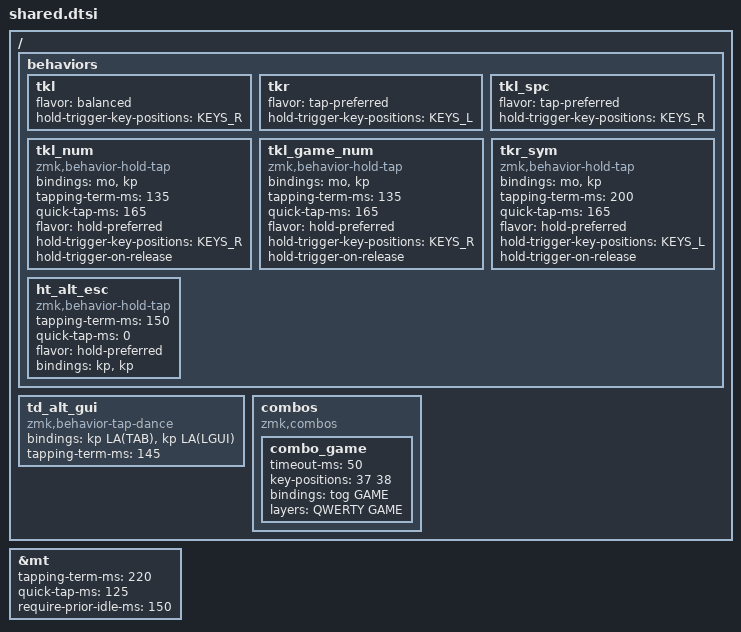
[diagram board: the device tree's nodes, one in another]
/* Key Positions
╭────────────────────────╮ ╭────────────────────────╮
│  0   1   2   3   4   5 │ │  6   7   8   9  10  11 │
│ 12  13  14  15  16  17 │ │ 18  19  20  21  22  23 │
│ 24  25  26  27  28  29 │ │ 30  31  32  33  34  35 │
╰───────────╮ 36  37  38 │ │ 39  40  41 ╭───────────╯
            ╰────────────╯ ╰────────────╯
*/


#define KEYS_L 0 1 2 3 4 5 12 13 14 15 16 17 24 25 26 27 28 29 36 37 38
#define KEYS_R 6 7 8 9 10 11 18 19 20 21 22 23 30 31 32 33 34 35 39 40 41

// layers
#define QWERTY    0
#define COLEMAK   1
#define GAME      2
#define GAME_NUM  3
#define NUM       4
#define FN        5
#define MEDIA     6
#define MOUSE     7
#define SYM       8

#define alt_esc      ht_alt_esc    LALT     ESC
#define fn_spc       tkl_spc       FN       SPACE
#define num_esc      tkl_num       NUM      ESC
#define game_num_esc tkl_game_num GAME_NUM ESC
#define mo_bspc      tkr           MOUSE    BSPC
#define sym_ret   tkr_sym    SYM      RET
#define media_del tkr        MEDIA    DEL

#define HOLD_TAP_BASE \
    compatible = "zmk,behavior-hold-tap"; \
    #binding-cells = <2>; \
    bindings = <&mo>, <&kp>; \
    tapping-term-ms = <165>; \
    quick-tap-ms = <145>; \
    require-prior-idle-ms = <100>;


&mt {
  tapping-term-ms = <220>;
  quick-tap-ms = <125>;
  require-prior-idle-ms = <150>;
};

/ {
  behaviors {
    tkl: tkl {
      HOLD_TAP_BASE
      flavor = "balanced";
      hold-trigger-key-positions = <KEYS_R>;
    };

    tkr: tkr {
      HOLD_TAP_BASE
      flavor = "tap-preferred";
      hold-trigger-key-positions = <KEYS_L>;
    };

    tkl_spc: tkl_spc {
      HOLD_TAP_BASE
      flavor = "tap-preferred";
      hold-trigger-key-positions = <KEYS_R>;
    };

    tkl_num: tkl_num {
      compatible = "zmk,behavior-hold-tap";
      #binding-cells = <2>;
      bindings = <&mo>, <&kp>;
      tapping-term-ms = <135>;
      quick-tap-ms = <165>;
      flavor = "hold-preferred";
      hold-trigger-key-positions = <KEYS_R>;
      hold-trigger-on-release;
    };

    tkl_game_num: tkl_game_num {
      compatible = "zmk,behavior-hold-tap";
      #binding-cells = <2>;
      bindings = <&mo>, <&kp>;
      tapping-term-ms = <135>;
      quick-tap-ms = <165>;
      flavor = "hold-preferred";
      hold-trigger-key-positions = <KEYS_R>;
      hold-trigger-on-release;
    };

    tkr_sym: tkr_sym {
      compatible = "zmk,behavior-hold-tap";
      #binding-cells = <2>;
      bindings = <&mo>, <&kp>;
      tapping-term-ms = <200>;
      quick-tap-ms = <165>;
      flavor = "hold-preferred";
      hold-trigger-key-positions = <KEYS_L>;
      hold-trigger-on-release;
    };

    ht_alt_esc: ht_alt_esc {
      compatible = "zmk,behavior-hold-tap";
      #binding-cells = <2>;
      tapping-term-ms = <150>;
      quick-tap-ms = <0>;
      flavor = "hold-preferred";
      bindings = <&kp>, <&kp>;
    };
  };

  td_alt_gui: td_alt_gui {
    compatible = "zmk,behavior-tap-dance";
    #binding-cells = <0>;
    bindings = <&kp LA(TAB)>, <&kp LA(LGUI)>;
    tapping-term-ms = <145>;
  };

  combos {
    compatible = "zmk,combos";
    combo_game {
      timeout-ms = <50>;
      key-positions = <37 38>;
      bindings = <&tog GAME>;
      layers = <QWERTY GAME>;
    };
  };
};
